# STM32WB30_CM4 register map
File version: 1.4-IAR
CPU: CM4 r0p1, little endian, MPU, FPU, 4 interrupt priority bits
Registers are 32-bit, read-write, reset 0x0 unless marked. A register's access mark holds for its fields unless they carry their own. Offsets are from the block's base; [hi:lo] are bit positions.

## IWDG — Independent watchdog
Base 0x40003000
0x00 KR wo — Key register
  [15:0] KEY — Key value (write only, read 0x0000)
0x04 PR — Prescaler register
  [2:0] PR — Prescaler divider
0x08 RLR reset 0xFFF — Reload register
  [11:0] RL — Watchdog counter reload value
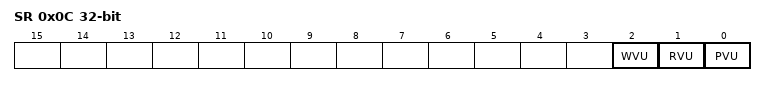
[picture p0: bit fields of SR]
0x0C SR ro — Status register
  [2] WVU — Watchdog counter window value update
  [1] RVU — Watchdog counter reload value update
  [0] PVU — Watchdog prescaler value update
0x10 WINR reset 0xFFF — Window register
  [11:0] WIN — Watchdog counter window value

## LPTIM1 — Low power timer
Base 0x40007C00
Same registers: LPTIM2 0x40009400
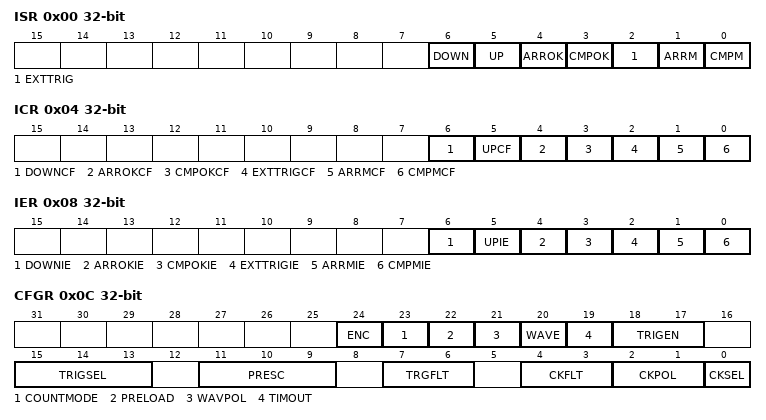
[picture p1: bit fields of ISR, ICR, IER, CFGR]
0x00 ISR ro — Interrupt and Status Register
  [6] DOWN — Counter direction change up to down
  [5] UP — Counter direction change down to up
  [4] ARROK — Autoreload register update OK
  [3] CMPOK — Compare register update OK
  [2] EXTTRIG — External trigger edge event
  [1] ARRM — Autoreload match
  [0] CMPM — Compare match
0x04 ICR wo — Interrupt Clear Register
  [6] DOWNCF — Direction change to down Clear Flag
  [5] UPCF — Direction change to UP Clear Flag
  [4] ARROKCF — Autoreload register update OK Clear Flag
  [3] CMPOKCF — Compare register update OK Clear Flag
  [2] EXTTRIGCF — External trigger valid edge Clear Flag
  [1] ARRMCF — Autoreload match Clear Flag
  [0] CMPMCF — compare match Clear Flag
0x08 IER — Interrupt Enable Register
  [6] DOWNIE — Direction change to down Interrupt Enable
  [5] UPIE — Direction change to UP Interrupt Enable
  [4] ARROKIE — Autoreload register update OK Interrupt Enable
  [3] CMPOKIE — Compare register update OK Interrupt Enable
  [2] EXTTRIGIE — External trigger valid edge Interrupt Enable
  [1] ARRMIE — Autoreload match Interrupt Enable
  [0] CMPMIE — Compare match Interrupt Enable
0x0C CFGR — Configuration Register
  [24] ENC — Encoder mode enable
  [23] COUNTMODE — counter mode enabled
  [22] PRELOAD — Registers update mode
  [21] WAVPOL — Waveform shape polarity
  [20] WAVE — Waveform shape
  [19] TIMOUT — Timeout enable
  [18:17] TRIGEN — Trigger enable and polarity
  [15:13] TRIGSEL — Trigger selector
  [11:9] PRESC — Clock prescaler
  [7:6] TRGFLT — Configurable digital filter for trigger
  [4:3] CKFLT — Configurable digital filter for external clock
  [2:1] CKPOL — Clock Polarity
  [0] CKSEL — Clock selector
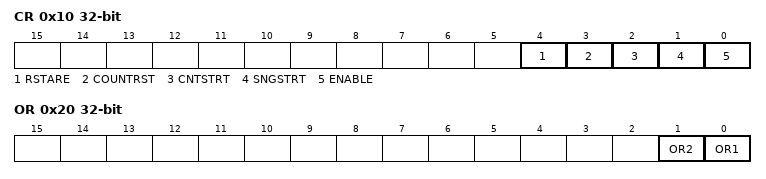
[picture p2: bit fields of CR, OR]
0x10 CR — Control Register
  [4] RSTARE — Reset after read enable
  [3] COUNTRST — Counter reset
  [2] CNTSTRT — Timer start in continuous mode
  [1] SNGSTRT — LPTIM start in single mode
  [0] ENABLE — LPTIM Enable
0x14 CMP — Compare Register
  [15:0] CMP — Compare value
0x18 ARR reset 0x1 — Autoreload Register
  [15:0] ARR — Auto reload value
0x1C CNT ro — Counter Register
  [15:0] CNT — Counter value
0x20 OR — Option Register
  [1] OR2 — Option register bit 2
  [0] OR1 — Option register bit 1

## MPU — Memory protection unit
Base 0xE000ED90
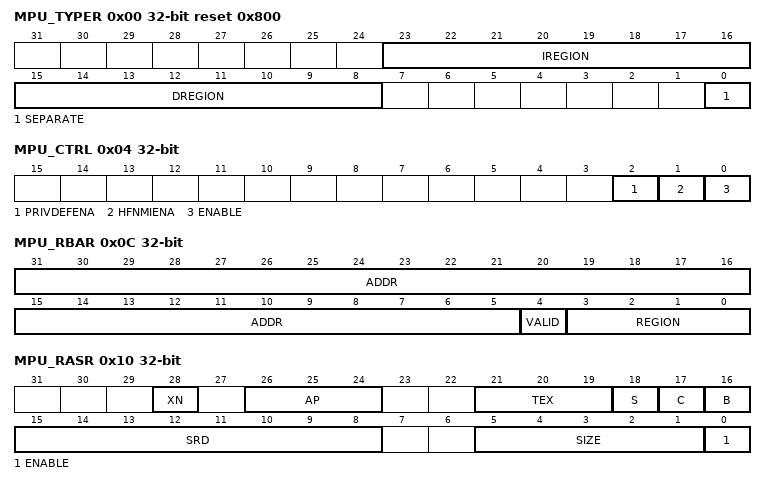
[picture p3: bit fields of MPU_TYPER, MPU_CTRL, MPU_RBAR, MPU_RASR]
0x00 MPU_TYPER ro reset 0x800 — MPU type register
  [23:16] IREGION — Number of MPU instruction regions
  [15:8] DREGION — Number of MPU data regions
  [0] SEPARATE — Separate flag
0x04 MPU_CTRL ro — MPU control register
  [2] PRIVDEFENA — Enable priviliged software access to default memory map
  [1] HFNMIENA — Enables the operation of MPU during hard fault
  [0] ENABLE — Enables the MPU
0x08 MPU_RNR — MPU region number register
  [7:0] REGION — MPU region
0x0C MPU_RBAR — MPU region base address register
  [31:5] ADDR — Region base address field
  [4] VALID — MPU region number valid
  [3:0] REGION — MPU region field
0x10 MPU_RASR — MPU region attribute and size register
  [28] XN — Instruction access disable bit
  [26:24] AP — Access permission
  [21:19] TEX — memory attribute
  [18] S — Shareable memory attribute
  [17] C — memory attribute
  [16] B — memory attribute
  [15:8] SRD — Subregion disable bits
  [5:1] SIZE — Size of the MPU protection region
  [0] ENABLE — Region enable bit.
